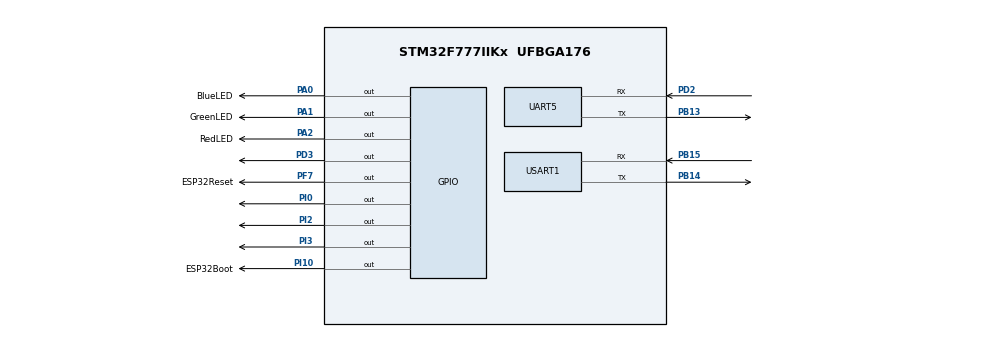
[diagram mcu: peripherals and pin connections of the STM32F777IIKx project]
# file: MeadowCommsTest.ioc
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Mcu.Family=STM32F7
Mcu.Name=STM32F777IIKx
Mcu.Package=UFBGA176
NVIC.PriorityGroup=NVIC_PRIORITYGROUP_4
NVIC.UART5_IRQn=true\:0\:0\:false\:false\:true\:true
NVIC.USART1_IRQn=true\:0\:0\:false\:false\:true\:true
PA0/WKUP.GPIO_Label=BlueLED
PA0/WKUP.Signal=GPIO_Output
PA1.GPIO_Label=GreenLED
PA1.Signal=GPIO_Output
PA2.GPIO_Label=RedLED
PA2.Signal=GPIO_Output
PB13.Mode=Asynchronous
PB13.Signal=UART5_TX
PB14.Mode=Asynchronous
PB14.Signal=USART1_TX
PB15.Mode=Asynchronous
PB15.Signal=USART1_RX
PD2.Mode=Asynchronous
PD2.Signal=UART5_RX
PD3.Signal=GPIO_Output
PF7.GPIO_Label=ESP32Reset
PF7.GPIO_PuPd=GPIO_PULLUP
PF7.PinState=GPIO_PIN_SET
PF7.Signal=GPIO_Output
PI0.Signal=GPIO_Output
PI10.GPIO_Label=ESP32Boot
PI10.GPIO_PuPd=GPIO_PULLUP
PI10.PinState=GPIO_PIN_SET
PI10.Signal=GPIO_Output
PI2.Signal=GPIO_Output
PI3.Signal=GPIO_Output
ProjectManager.HeapSize=0x200
ProjectManager.StackSize=0x400
ProjectManager.TargetToolchain=Makefile
RCC.HSE_VALUE=25000000
RCC.HSI_VALUE=16000000
RCC.LSE_VALUE=32768
RCC.USBFreq_Value=96000000
RCC.VCOOutputFreq_Value=192000000
USART1.VirtualMode-Asynchronous=VM_ASYNC
board=custom

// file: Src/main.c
/* USER CODE BEGIN Header */
/**
  ******************************************************************************
  * @file           : main.c
  * @brief          : Main program body
  ******************************************************************************
  ** This notice applies to any and all portions of this file
  * that are not between comment pairs USER CODE BEGIN and
  * USER CODE END. Other portions of this file, whether
  * inserted by the user or by software development tools
  * are owned by their respective copyright owners.
  *
  * COPYRIGHT(c) 2019 STMicroelectronics
  *
  * Redistribution and use in source and binary forms, with or without modification,
  * are permitted provided that the following conditions are met:
  *   1. Redistributions of source code must retain the above copyright notice,
  *      this list of conditions and the following disclaimer.
  *   2. Redistributions in binary form must reproduce the above copyright notice,
  *      this list of conditions and the following disclaimer in the documentation
  *      and/or other materials provided with the distribution.
  *   3. Neither the name of STMicroelectronics nor the names of its contributors
  *      may be used to endorse or promote products derived from this software
  *      without specific prior written permission.
  *
  * THIS SOFTWARE IS PROVIDED BY THE COPYRIGHT HOLDERS AND CONTRIBUTORS "AS IS"
  * AND ANY EXPRESS OR IMPLIED WARRANTIES, INCLUDING, BUT NOT LIMITED TO, THE
  * IMPLIED WARRANTIES OF MERCHANTABILITY AND FITNESS FOR A PARTICULAR PURPOSE ARE
  * DISCLAIMED. IN NO EVENT SHALL THE COPYRIGHT HOLDER OR CONTRIBUTORS BE LIABLE
  * FOR ANY DIRECT, INDIRECT, INCIDENTAL, SPECIAL, EXEMPLARY, OR CONSEQUENTIAL
  * DAMAGES (INCLUDING, BUT NOT LIMITED TO, PROCUREMENT OF SUBSTITUTE GOODS OR
  * SERVICES; LOSS OF USE, DATA, OR PROFITS; OR BUSINESS INTERRUPTION) HOWEVER
  * CAUSED AND ON ANY THEORY OF LIABILITY, WHETHER IN CONTRACT, STRICT LIABILITY,
  * OR TORT (INCLUDING NEGLIGENCE OR OTHERWISE) ARISING IN ANY WAY OUT OF THE USE
  * OF THIS SOFTWARE, EVEN IF ADVISED OF THE POSSIBILITY OF SUCH DAMAGE.
  *
  ******************************************************************************
  */
/* USER CODE END Header */

#include "main.h"

/* USER CODE BEGIN Includes */

#include <string.h>
#include "ESPFunctions.h"

/* USER CODE END Includes */

UART_HandleTypeDef huart5;
UART_HandleTypeDef huart1;

/* USER CODE BEGIN PV */

/*
 *    Hold the data generated by the interrupt.
 */
char _rxData[2];

/*
 *    Hold the accumulated data incoming from the UART.
 */
#define RX_BUFFER_CAPACITY 1000
char _rxBuffer[RX_BUFFER_CAPACITY];

/*
 *    Location of the next character in the accumulated buffer.
 */
uint8_t _rxIndex;

/* USER CODE END PV */

void SystemClock_Config(void);
static void MX_GPIO_Init(void);
static void MX_USART1_UART_Init(void);
static void MX_UART5_Init(void);

/* USER CODE BEGIN 0 */

/*
 *    @brief UART Data Received callback.
 *
 *    @param huart
 *      Handle for the UART generating the interrupt.
 */
void HAL_UART_RxCpltCallback(UART_HandleTypeDef *huart)
{
}

/*
 *    Send the specified message to the UART.
 */
void SendMessageToConsole(char *message)
{
  HAL_UART_Transmit(&huart1, (uint8_t *)message, strlen(message), HAL_MAX_DELAY);
}

/* USER CODE END 0 */

int main(void)
{

  /* MCU Configuration--------------------------------------------------------*/

  /* Reset of all peripherals, Initializes the Flash interface and the Systick. */
  HAL_Init();

  /* Configure the system clock */
  SystemClock_Config();

  /* Initialize all configured peripherals */
  MX_GPIO_Init();
  MX_USART1_UART_Init();
  MX_UART5_Init();
  /* USER CODE BEGIN 2 */

  HAL_GPIO_WritePin(BlueLED_GPIO_Port, BlueLED_Pin, GPIO_PIN_SET);
  HAL_GPIO_WritePin(RedLED_GPIO_Port, RedLED_Pin, GPIO_PIN_SET);
  HAL_UART_Receive_IT(&huart5, (uint8_t *)_rxData, 1);

  /* USER CODE END 2 */

  /* Infinite loop */
  /* USER CODE BEGIN WHILE */

  SendMessageToConsole("Restarting the ESP32 and witing for 1 second\n");
  HAL_GPIO_WritePin(ESP32Boot_GPIO_Port, ESP32Boot_Pin, GPIO_PIN_SET);
  HAL_GPIO_WritePin(ESP32Reset_GPIO_Port, ESP32Reset_Pin, GPIO_PIN_RESET);
  HAL_Delay(10);
  HAL_GPIO_WritePin(ESP32Reset_GPIO_Port, ESP32Reset_Pin, GPIO_PIN_SET);
  HAL_Delay(1);
  HAL_GPIO_WritePin(ESP32Boot_GPIO_Port, ESP32Boot_Pin, GPIO_PIN_RESET);
  HAL_Delay(1000);
  SendMessageToConsole("Toggling to Boot pin\n");
  HAL_GPIO_TogglePin(ESP32Boot_GPIO_Port, ESP32Boot_Pin);
  HAL_Delay(50);
  HAL_GPIO_TogglePin(ESP32Boot_GPIO_Port, ESP32Boot_Pin);
  HAL_Delay(50);
  HAL_GPIO_TogglePin(ESP32Boot_GPIO_Port, ESP32Boot_Pin);
  HAL_Delay(50);
  HAL_GPIO_TogglePin(ESP32Boot_GPIO_Port, ESP32Boot_Pin);
  SendMessageToConsole("Exiting.\n");
}

void SystemClock_Config(void)
{
  RCC_OscInitTypeDef RCC_OscInitStruct = {0};
  RCC_ClkInitTypeDef RCC_ClkInitStruct = {0};
  RCC_PeriphCLKInitTypeDef PeriphClkInitStruct = {0};

  /**Configure the main internal regulator output voltage
  */
  __HAL_RCC_PWR_CLK_ENABLE();
  __HAL_PWR_VOLTAGESCALING_CONFIG(PWR_REGULATOR_VOLTAGE_SCALE3);
  /**Initializes the CPU, AHB and APB busses clocks
  */
  RCC_OscInitStruct.OscillatorType = RCC_OSCILLATORTYPE_HSI;
  RCC_OscInitStruct.HSIState = RCC_HSI_ON;
  RCC_OscInitStruct.HSICalibrationValue = RCC_HSICALIBRATION_DEFAULT;
  RCC_OscInitStruct.PLL.PLLState = RCC_PLL_NONE;
  if (HAL_RCC_OscConfig(&RCC_OscInitStruct) != HAL_OK)
  {
    Error_Handler();
  }
  /**Initializes the CPU, AHB and APB busses clocks
  */
  RCC_ClkInitStruct.ClockType = RCC_CLOCKTYPE_HCLK | RCC_CLOCKTYPE_SYSCLK | RCC_CLOCKTYPE_PCLK1 | RCC_CLOCKTYPE_PCLK2;
  RCC_ClkInitStruct.SYSCLKSource = RCC_SYSCLKSOURCE_HSI;
  RCC_ClkInitStruct.AHBCLKDivider = RCC_SYSCLK_DIV1;
  RCC_ClkInitStruct.APB1CLKDivider = RCC_HCLK_DIV1;
  RCC_ClkInitStruct.APB2CLKDivider = RCC_HCLK_DIV1;

  if (HAL_RCC_ClockConfig(&RCC_ClkInitStruct, FLASH_LATENCY_0) != HAL_OK)
  {
    Error_Handler();
  }
  PeriphClkInitStruct.PeriphClockSelection = RCC_PERIPHCLK_USART1 | RCC_PERIPHCLK_UART5;
  PeriphClkInitStruct.Usart1ClockSelection = RCC_USART1CLKSOURCE_PCLK2;
  PeriphClkInitStruct.Uart5ClockSelection = RCC_UART5CLKSOURCE_PCLK1;
  if (HAL_RCCEx_PeriphCLKConfig(&PeriphClkInitStruct) != HAL_OK)
  {
    Error_Handler();
  }
}

static void MX_UART5_Init(void)
{

  huart5.Instance = UART5;
  huart5.Init.BaudRate = 115200;
  huart5.Init.WordLength = UART_WORDLENGTH_8B;
  huart5.Init.StopBits = UART_STOPBITS_1;
  huart5.Init.Parity = UART_PARITY_NONE;
  huart5.Init.Mode = UART_MODE_TX_RX;
  huart5.Init.HwFlowCtl = UART_HWCONTROL_NONE;
  huart5.Init.OverSampling = UART_OVERSAMPLING_16;
  huart5.Init.OneBitSampling = UART_ONE_BIT_SAMPLE_DISABLE;
  huart5.AdvancedInit.AdvFeatureInit = UART_ADVFEATURE_NO_INIT;
  if (HAL_UART_Init(&huart5) != HAL_OK)
  {
    Error_Handler();
  }
}

static void MX_USART1_UART_Init(void)
{

  huart1.Instance = USART1;
  huart1.Init.BaudRate = 115200;
  huart1.Init.WordLength = UART_WORDLENGTH_8B;
  huart1.Init.StopBits = UART_STOPBITS_1;
  huart1.Init.Parity = UART_PARITY_NONE;
  huart1.Init.Mode = UART_MODE_TX_RX;
  huart1.Init.HwFlowCtl = UART_HWCONTROL_NONE;
  huart1.Init.OverSampling = UART_OVERSAMPLING_16;
  huart1.Init.OneBitSampling = UART_ONE_BIT_SAMPLE_DISABLE;
  huart1.AdvancedInit.AdvFeatureInit = UART_ADVFEATURE_NO_INIT;
  if (HAL_UART_Init(&huart1) != HAL_OK)
  {
    Error_Handler();
  }
}

static void MX_GPIO_Init(void)
{
  GPIO_InitTypeDef GPIO_InitStruct = {0};

  /* GPIO Ports Clock Enable */
  __HAL_RCC_GPIOI_CLK_ENABLE();
  __HAL_RCC_GPIOD_CLK_ENABLE();
  __HAL_RCC_GPIOF_CLK_ENABLE();
  __HAL_RCC_GPIOA_CLK_ENABLE();
  __HAL_RCC_GPIOB_CLK_ENABLE();

  /*Configure GPIO pin Output Level */
  HAL_GPIO_WritePin(GPIOI, GPIO_PIN_3 | GPIO_PIN_2 | GPIO_PIN_0, GPIO_PIN_RESET);

  /*Configure GPIO pin Output Level */
  HAL_GPIO_WritePin(GPIOD, GPIO_PIN_3, GPIO_PIN_RESET);

  /*Configure GPIO pin Output Level */
  HAL_GPIO_WritePin(ESP32Boot_GPIO_Port, ESP32Boot_Pin, GPIO_PIN_RESET);

  /*Configure GPIO pin Output Level */
  HAL_GPIO_WritePin(ESP32Reset_GPIO_Port, ESP32Reset_Pin, GPIO_PIN_SET);

  /*Configure GPIO pin Output Level */
  HAL_GPIO_WritePin(GPIOA, GreenLED_Pin | BlueLED_Pin | RedLED_Pin, GPIO_PIN_RESET);

  /*Configure GPIO pins : PI3 PI2 PI0 */
  GPIO_InitStruct.Pin = GPIO_PIN_3 | GPIO_PIN_2 | GPIO_PIN_0;
  GPIO_InitStruct.Mode = GPIO_MODE_OUTPUT_PP;
  GPIO_InitStruct.Pull = GPIO_NOPULL;
  GPIO_InitStruct.Speed = GPIO_SPEED_FREQ_LOW;
  HAL_GPIO_Init(GPIOI, &GPIO_InitStruct);

  /*Configure GPIO pin : PD3 */
  GPIO_InitStruct.Pin = GPIO_PIN_3;
  GPIO_InitStruct.Mode = GPIO_MODE_OUTPUT_PP;
  GPIO_InitStruct.Pull = GPIO_NOPULL;
  GPIO_InitStruct.Speed = GPIO_SPEED_FREQ_LOW;
  HAL_GPIO_Init(GPIOD, &GPIO_InitStruct);

  /*Configure GPIO pin : ESP32Boot_Pin */
  GPIO_InitStruct.Pin = ESP32Boot_Pin;
  GPIO_InitStruct.Mode = GPIO_MODE_OUTPUT_PP;
  GPIO_InitStruct.Pull = GPIO_PULLUP;
  GPIO_InitStruct.Speed = GPIO_SPEED_FREQ_LOW;
  HAL_GPIO_Init(ESP32Boot_GPIO_Port, &GPIO_InitStruct);

  /*Configure GPIO pin : ESP32Reset_Pin */
  GPIO_InitStruct.Pin = ESP32Reset_Pin;
  GPIO_InitStruct.Mode = GPIO_MODE_OUTPUT_PP;
  GPIO_InitStruct.Pull = GPIO_PULLUP;
  GPIO_InitStruct.Speed = GPIO_SPEED_FREQ_LOW;
  HAL_GPIO_Init(ESP32Reset_GPIO_Port, &GPIO_InitStruct);

  /*Configure GPIO pins : GreenLED_Pin BlueLED_Pin RedLED_Pin */
  GPIO_InitStruct.Pin = GreenLED_Pin | BlueLED_Pin | RedLED_Pin;
  GPIO_InitStruct.Mode = GPIO_MODE_OUTPUT_PP;
  GPIO_InitStruct.Pull = GPIO_NOPULL;
  GPIO_InitStruct.Speed = GPIO_SPEED_FREQ_LOW;
  HAL_GPIO_Init(GPIOA, &GPIO_InitStruct);
}

void Error_Handler(void)
{
}

/************************ (C) COPYRIGHT STMicroelectronics *****END OF FILE****/
